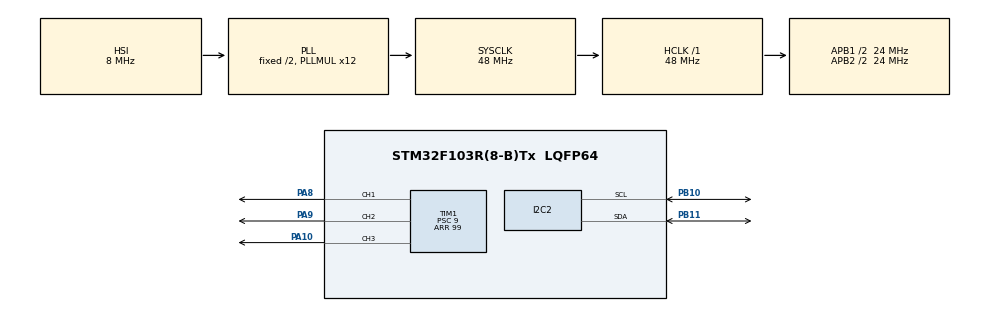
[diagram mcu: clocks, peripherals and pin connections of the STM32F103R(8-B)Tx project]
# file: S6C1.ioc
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Mcu.Family=STM32F1
Mcu.Name=STM32F103R(8-B)Tx
Mcu.Package=LQFP64
NVIC.PriorityGroup=NVIC_PRIORITYGROUP_4
PA10.Signal=S_TIM1_CH3
PA13.Mode=Serial_Wire
PA13.Signal=SYS_JTMS-SWDIO
PA14.Mode=Serial_Wire
PA14.Signal=SYS_JTCK-SWCLK
PA8.Signal=S_TIM1_CH1
PA9.Signal=S_TIM1_CH2
PB10.Mode=I2C
PB10.Signal=I2C2_SCL
PB11.Mode=I2C
PB11.Signal=I2C2_SDA
ProjectManager.TargetToolchain=SW4STM32
RCC.AHBFreq_Value=48000000
RCC.APB1CLKDivider=RCC_HCLK_DIV2
RCC.APB1Freq_Value=24000000
RCC.APB1TimCLKDivider=1
RCC.APB1TimFreq_Value=24000000
RCC.APB2CLKDivider=RCC_HCLK_DIV2
RCC.APB2Freq_Value=24000000
RCC.APB2TimFreq_Value=48000000
RCC.HCLKFreq_Value=48000000
RCC.PLLMUL=RCC_PLL_MUL12
RCC.SYSCLKFreq_VALUE=48000000
RCC.SYSCLKSource=RCC_SYSCLKSOURCE_PLLCLK
RCC.USBFreq_Value=48000000
SH.S_TIM1_CH1.0=TIM1_CH1,PWM Generation1 CH1
SH.S_TIM1_CH2.0=TIM1_CH2,PWM Generation2 CH2
SH.S_TIM1_CH3.0=TIM1_CH3,PWM Generation3 CH3
TIM1.Channel-PWM\ Generation2\ CH2=TIM_CHANNEL_2
TIM1.Channel-PWM\ Generation3\ CH3=TIM_CHANNEL_3
TIM1.Period=99
TIM1.Prescaler=9
VP_TIM1_VS_ClockSourceINT.Mode=Internal
board=S6C1

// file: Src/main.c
/**
  ******************************************************************************
  * File Name          : main.c
  * Description        : Main program body
  ******************************************************************************
  *
  * COPYRIGHT(c) 2016 STMicroelectronics
  *
  * Redistribution and use in source and binary forms, with or without modification,
  * are permitted provided that the following conditions are met:
  *   1. Redistributions of source code must retain the above copyright notice,
  *      this list of conditions and the following disclaimer.
  *   2. Redistributions in binary form must reproduce the above copyright notice,
  *      this list of conditions and the following disclaimer in the documentation
  *      and/or other materials provided with the distribution.
  *   3. Neither the name of STMicroelectronics nor the names of its contributors
  *      may be used to endorse or promote products derived from this software
  *      without specific prior written permission.
  *
  * THIS SOFTWARE IS PROVIDED BY THE COPYRIGHT HOLDERS AND CONTRIBUTORS "AS IS"
  * AND ANY EXPRESS OR IMPLIED WARRANTIES, INCLUDING, BUT NOT LIMITED TO, THE
  * IMPLIED WARRANTIES OF MERCHANTABILITY AND FITNESS FOR A PARTICULAR PURPOSE ARE
  * DISCLAIMED. IN NO EVENT SHALL THE COPYRIGHT HOLDER OR CONTRIBUTORS BE LIABLE
  * FOR ANY DIRECT, INDIRECT, INCIDENTAL, SPECIAL, EXEMPLARY, OR CONSEQUENTIAL
  * DAMAGES (INCLUDING, BUT NOT LIMITED TO, PROCUREMENT OF SUBSTITUTE GOODS OR
  * SERVICES; LOSS OF USE, DATA, OR PROFITS; OR BUSINESS INTERRUPTION) HOWEVER
  * CAUSED AND ON ANY THEORY OF LIABILITY, WHETHER IN CONTRACT, STRICT LIABILITY,
  * OR TORT (INCLUDING NEGLIGENCE OR OTHERWISE) ARISING IN ANY WAY OUT OF THE USE
  * OF THIS SOFTWARE, EVEN IF ADVISED OF THE POSSIBILITY OF SUCH DAMAGE.
  *
  ******************************************************************************
  */
#include "stm32f1xx_hal.h"
#include "i2c.h"
#include "tim.h"
#include "gpio.h"

/* USER CODE BEGIN PV */
/* Private variables ---------------------------------------------------------*/

/* USER CODE END PV */

void SystemClock_Config(void);

/* USER CODE BEGIN PFP */
/* Private function prototypes -----------------------------------------------*/

/* USER CODE END PFP */

int main(void)
{

  /* USER CODE BEGIN 1 */
	uint8_t MemRead= 0;
	uint8_t MemWrite = 32;
  /* USER CODE END 1 */

  /* MCU Configuration----------------------------------------------------------*/

  /* Reset of all peripherals, Initializes the Flash interface and the Systick. */
  HAL_Init();

  /* Configure the system clock */
  SystemClock_Config();

  /* Initialize all configured peripherals */
  MX_GPIO_Init();
  MX_I2C2_Init();
  MX_TIM1_Init();

  /* USER CODE BEGIN 2 */
  HAL_TIM_PWM_Start(&htim1,TIM_CHANNEL_1);
  HAL_TIM_PWM_Start(&htim1,TIM_CHANNEL_2);
  HAL_TIM_PWM_Start(&htim1,TIM_CHANNEL_3);

  HAL_I2C_Mem_Read(&hi2c2,0xA0,0,1,&MemRead,1,100);
  HAL_I2C_Mem_Write(&hi2c2,0xA0,0,1,&MemWrite,1,100);
  HAL_I2C_Mem_Read(&hi2c2,0xA0,0,1,&MemRead,1,100);
  if(MemRead == MemWrite)
  {
	  HAL_GPIO_TogglePin()
  }
  /* USER CODE END 2 */

  /* Infinite loop */
  while (1)
  {
	  TIM1->CCR1 = 50;
	  TIM1->CCR2 = 100;
	  TIM1->CCR3 = 0;

  }

}

/** System Clock Configuration
*/
void SystemClock_Config(void)
{

  RCC_OscInitTypeDef RCC_OscInitStruct;
  RCC_ClkInitTypeDef RCC_ClkInitStruct;

  RCC_OscInitStruct.OscillatorType = RCC_OSCILLATORTYPE_HSI;
  RCC_OscInitStruct.HSIState = RCC_HSI_ON;
  RCC_OscInitStruct.HSICalibrationValue = 16;
  RCC_OscInitStruct.PLL.PLLState = RCC_PLL_ON;
  RCC_OscInitStruct.PLL.PLLSource = RCC_PLLSOURCE_HSI_DIV2;
  RCC_OscInitStruct.PLL.PLLMUL = RCC_PLL_MUL12;
  HAL_RCC_OscConfig(&RCC_OscInitStruct);

  RCC_ClkInitStruct.ClockType = RCC_CLOCKTYPE_SYSCLK|RCC_CLOCKTYPE_PCLK1
                              |RCC_CLOCKTYPE_PCLK2;
  RCC_ClkInitStruct.SYSCLKSource = RCC_SYSCLKSOURCE_PLLCLK;
  RCC_ClkInitStruct.AHBCLKDivider = RCC_SYSCLK_DIV1;
  RCC_ClkInitStruct.APB1CLKDivider = RCC_HCLK_DIV2;
  RCC_ClkInitStruct.APB2CLKDivider = RCC_HCLK_DIV2;
  HAL_RCC_ClockConfig(&RCC_ClkInitStruct, FLASH_LATENCY_1);

  HAL_SYSTICK_Config(HAL_RCC_GetHCLKFreq()/1000);

  HAL_SYSTICK_CLKSourceConfig(SYSTICK_CLKSOURCE_HCLK);

  /* SysTick_IRQn interrupt configuration */
  HAL_NVIC_SetPriority(SysTick_IRQn, 0, 0);
}

/************************ (C) COPYRIGHT STMicroelectronics *****END OF FILE****/
